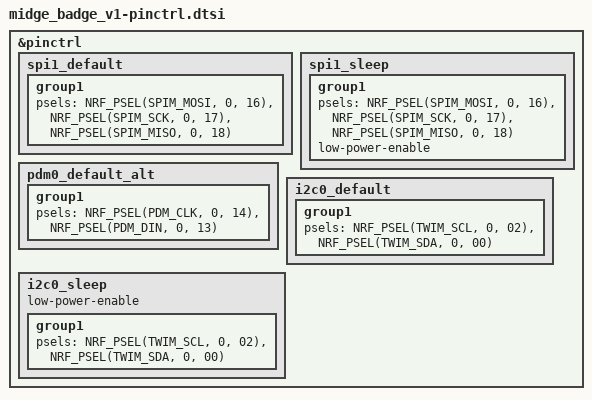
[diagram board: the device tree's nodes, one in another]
&pinctrl {
	spi1_default: spi1_default {
		group1 {
			psels = <NRF_PSEL(SPIM_MOSI, 0, 16)>, <NRF_PSEL(SPIM_SCK, 0, 17)>, <NRF_PSEL(SPIM_MISO, 0, 18)>;
		};
	};

	spi1_sleep: spi1_sleep {
		group1 {
			psels = <NRF_PSEL(SPIM_MOSI, 0, 16)>, <NRF_PSEL(SPIM_SCK, 0, 17)>,<NRF_PSEL(SPIM_MISO, 0, 18)>;
			low-power-enable;
		};
	};

	pdm0_default_alt: pdm0_default_alt {
		group1 {
			psels = <NRF_PSEL(PDM_CLK, 0, 14)>,
				<NRF_PSEL(PDM_DIN, 0, 13)>;
		};
	};

	i2c0_default: i2c0_default {
		group1 {
			psels = <NRF_PSEL(TWIM_SCL, 0, 02)>, <NRF_PSEL(TWIM_SDA, 0, 00)>;
		};
	};

	i2c0_sleep: i2c0_sleep {
		group1 {
			psels = <NRF_PSEL(TWIM_SCL, 0, 02)>, <NRF_PSEL(TWIM_SDA, 0, 00)>;
		};
		low-power-enable;
	};
};
